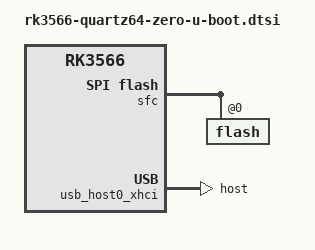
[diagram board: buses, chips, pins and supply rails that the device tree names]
// SPDX-License-Identifier: GPL-2.0+

#include "rk356x-u-boot.dtsi"

&sdhci {
	cap-mmc-highspeed;
	pinctrl-names = "default";
	pinctrl-0 = <&emmc_bus8 &emmc_clk &emmc_cmd &emmc_datastrobe>;
};

&sfc {
	flash@0 {
		bootph-pre-ram;
		bootph-some-ram;
	};
};

&usb_host0_xhci {
	dr_mode = "host";
};

&vcc5v0_usb_host {
	/delete-property/ regulator-always-on;
};

&vcc5v0_usb_otg {
	/delete-property/ regulator-always-on;
};
